AUTOSAR XML (schema 00048)
package /ComponentTypes
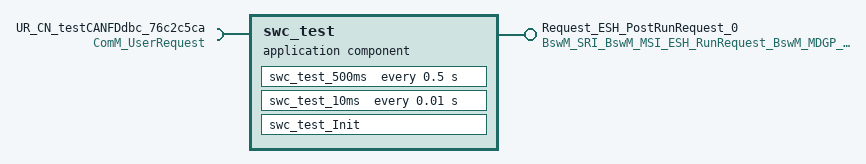
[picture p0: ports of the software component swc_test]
  application sw component type swc_test
    provide port Request_ESH_PostRunRequest_0: nonqueued-sender-com-spec=requestedMode, provided-interface=BswM_SRI_BswM_MSI_ESH_RunRequest_BswM_MDGP_ESH_RunRequest
    require port UR_CN_testCANFDdbc_76c2c5ca: required-com-specs=[RequestComMode, GetCurrentComMode, GetMaxComMode, GetRequestedComMode], required-interface=ComM_UserRequest
    behavior swc_test_InternalBehavior
      init event swc_test_InitEvent: start-on-event=swc_test_Init
      timing event TMT_swc_test_500ms: start-on-event=swc_test_500ms, period=0.5
      timing event TMT_swc_test_10ms: start-on-event=swc_test_10ms, period=0.01
      runnable swc_test_Init
        data-send-points:
          access SEND_Request_ESH_PostRunRequest_0_requestedMode: accessed-variable=Request_ESH_PostRunRequest_0.requestedMode
        sync call SC_UR_CN_testCANFDdbc_76c2c5ca_RequestComMode: operation=UR_CN_testCANFDdbc_76c2c5ca.RequestComMode
      runnable swc_test_500ms
      runnable swc_test_10ms
  swc implementation swc_test_Implementation: behavior=swc_test_InternalBehavior
